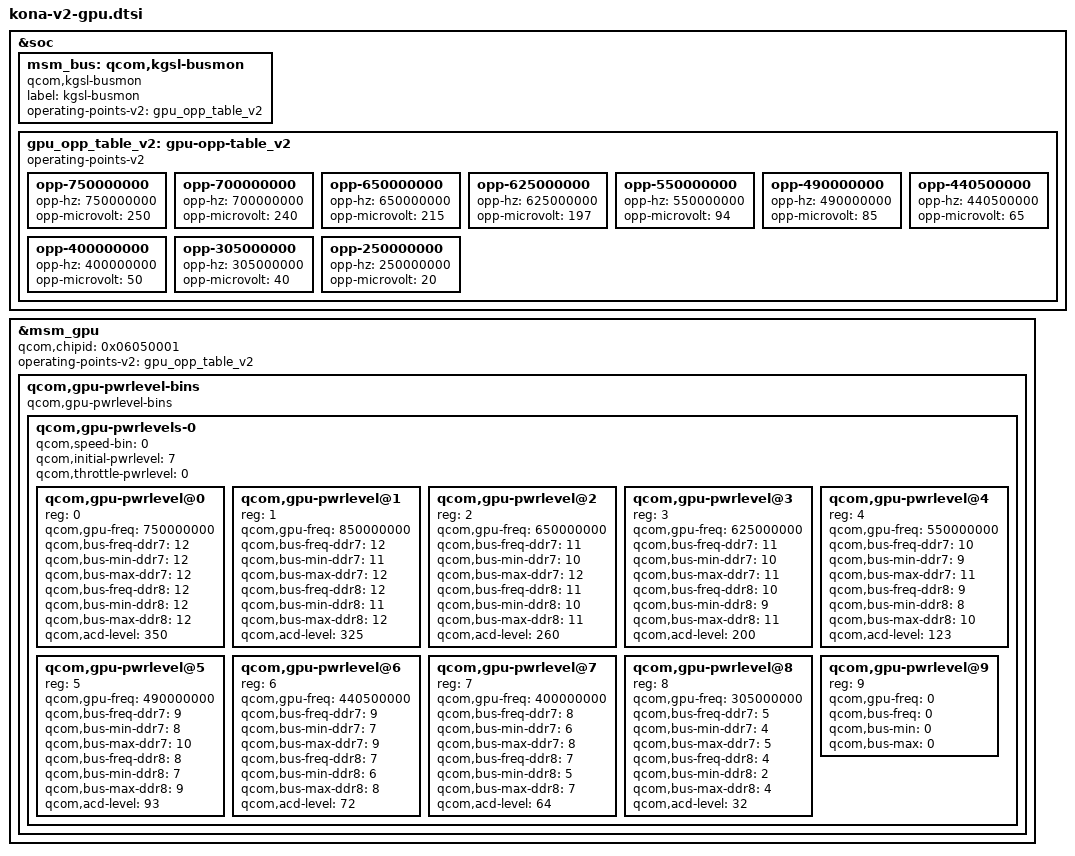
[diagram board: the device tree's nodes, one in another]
&soc {
	msm_bus: qcom,kgsl-busmon {
		label = "kgsl-busmon";
		compatible = "qcom,kgsl-busmon";
		operating-points-v2 = <&gpu_opp_table_v2>;
	};

	gpu_opp_table_v2: gpu-opp-table_v2 {
		compatible = "operating-points-v2";
		
		opp-750000000 {
			opp-hz = /bits/ 64 <750000000>;
			opp-microvolt = <250>;
		};

		opp-700000000 {
			opp-hz = /bits/ 64 <700000000>;
			opp-microvolt = <240>;
		};
		
		opp-650000000 {
			opp-hz = /bits/ 64 <650000000>;
			opp-microvolt = <215>;
		};

		opp-625000000 {
			opp-hz = /bits/ 64 <625000000>;
			opp-microvolt = <197>;
		};

		opp-550000000 {
			opp-hz = /bits/ 64 <550000000>;
			opp-microvolt = <94>;
		};

		opp-490000000 {
			opp-hz = /bits/ 64 <490000000>;
			opp-microvolt = <85>;
		};

		opp-440500000 {
			opp-hz = /bits/ 64 <440500000>;
			opp-microvolt = <65>;
		};

		opp-400000000 {
			opp-hz = /bits/ 64 <400000000>;
			opp-microvolt = <50>;
		};

		opp-305000000 {
			opp-hz = /bits/ 64 <305000000>;
			opp-microvolt = <40>;
		};

		opp-250000000 {
			opp-hz = /bits/ 64 <250000000>;
			opp-microvolt = <20>;
		};
	};
};

&msm_gpu {
	qcom,chipid = <0x06050001>;

	/* GPU OPP data */
	operating-points-v2 = <&gpu_opp_table_v2>;

	/delete-property/qcom,initial-pwrlevel;
	/delete-node/qcom,gpu-pwrlevels;

	/* Power levels bins */
	qcom,gpu-pwrlevel-bins {
		compatible="qcom,gpu-pwrlevel-bins";
		#address-cells = <1>;
		#size-cells = <0>;

		 qcom,gpu-pwrlevels-0 {
			#address-cells = <1>;
			#size-cells = <0>;
			qcom,speed-bin = <0>;
			qcom,initial-pwrlevel = <7>;
			qcom,throttle-pwrlevel = <0>;

			qcom,gpu-pwrlevel@0 {
				reg = <0>;
				qcom,gpu-freq = <750000000>;
				qcom,bus-freq-ddr7 = <12>;
				qcom,bus-min-ddr7 = <12>;
				qcom,bus-max-ddr7 = <12>;

				qcom,bus-freq-ddr8 = <12>;
				qcom,bus-min-ddr8 = <12>;
				qcom,bus-max-ddr8 = <12>;

				qcom,acd-level = <350>;
			};
			
			qcom,gpu-pwrlevel@1 {
				reg = <1>;
				qcom,gpu-freq = <850000000>;
				qcom,bus-freq-ddr7 = <12>;
				qcom,bus-min-ddr7 = <11>;
				qcom,bus-max-ddr7 = <12>;

				qcom,bus-freq-ddr8 = <12>;
				qcom,bus-min-ddr8 = <11>;
				qcom,bus-max-ddr8 = <12>;

				qcom,acd-level = <325>;
			};

			qcom,gpu-pwrlevel@2 {
				reg = <2>;
				qcom,gpu-freq = <650000000>;
				qcom,bus-freq-ddr7 = <11>;
				qcom,bus-min-ddr7 = <10>;
				qcom,bus-max-ddr7 = <12>;

				qcom,bus-freq-ddr8 = <11>;
				qcom,bus-min-ddr8 = <10>;
				qcom,bus-max-ddr8 = <11>;

				qcom,acd-level = <260>;
			};

			qcom,gpu-pwrlevel@3 {
				reg = <3>;
				qcom,gpu-freq = <625000000>;
				qcom,bus-freq-ddr7 = <11>;
				qcom,bus-min-ddr7 = <10>;
				qcom,bus-max-ddr7 = <11>;

				qcom,bus-freq-ddr8 = <10>;
				qcom,bus-min-ddr8 = <9>;
				qcom,bus-max-ddr8 = <11>;

				qcom,acd-level = <200>;
			};

			qcom,gpu-pwrlevel@4 {
				reg = <4>;
				qcom,gpu-freq = <550000000>;
				qcom,bus-freq-ddr7 = <10>;
				qcom,bus-min-ddr7 = <9>;
				qcom,bus-max-ddr7 = <11>;

				qcom,bus-freq-ddr8 = <9>;
				qcom,bus-min-ddr8 = <8>;
				qcom,bus-max-ddr8 = <10>;

				qcom,acd-level = <123>;
			};

			qcom,gpu-pwrlevel@5 {
				reg = <5>;
				qcom,gpu-freq = <490000000>;
				qcom,bus-freq-ddr7 = <9>;
				qcom,bus-min-ddr7 = <8>;
				qcom,bus-max-ddr7 = <10>;

				qcom,bus-freq-ddr8 = <8>;
				qcom,bus-min-ddr8 = <7>;
				qcom,bus-max-ddr8 = <9>;

				qcom,acd-level = <93>;
				};

			qcom,gpu-pwrlevel@6 {
				reg = <6>;
				qcom,gpu-freq = <440500000>;
				qcom,bus-freq-ddr7 = <9>;
				qcom,bus-min-ddr7 = <7>;
				qcom,bus-max-ddr7 = <9>;

				qcom,bus-freq-ddr8 = <7>;
				qcom,bus-min-ddr8 = <6>;
				qcom,bus-max-ddr8 = <8>;

				qcom,acd-level = <72>;
			};

			qcom,gpu-pwrlevel@7 {
				reg = <7>;
				qcom,gpu-freq = <400000000>;
				qcom,bus-freq-ddr7 = <8>;
				qcom,bus-min-ddr7 = <6>;
				qcom,bus-max-ddr7 = <8>;

				qcom,bus-freq-ddr8 = <7>;
				qcom,bus-min-ddr8 = <5>;
				qcom,bus-max-ddr8 = <7>;

				qcom,acd-level = <64>;
			};

			qcom,gpu-pwrlevel@8 {
				reg = <8>;
				qcom,gpu-freq = <305000000>;
				qcom,bus-freq-ddr7 = <5>;
				qcom,bus-min-ddr7 = <4>;
				qcom,bus-max-ddr7 = <5>;

				qcom,bus-freq-ddr8 = <4>;
				qcom,bus-min-ddr8 = <2>;
				qcom,bus-max-ddr8 = <4>;

				qcom,acd-level = <32>;
			};

			qcom,gpu-pwrlevel@9 {
				reg = <9>;
				qcom,gpu-freq = <0>;
				qcom,bus-freq = <0>;
				qcom,bus-min = <0>;
				qcom,bus-max = <0>;
			};
		};
	};
};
